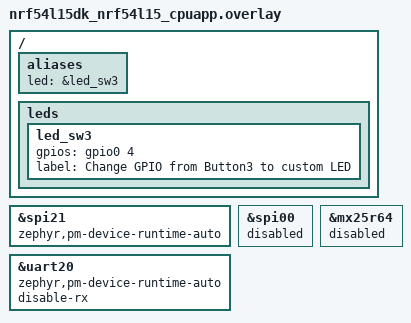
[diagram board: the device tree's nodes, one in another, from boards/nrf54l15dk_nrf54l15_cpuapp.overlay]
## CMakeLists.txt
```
#
# Copyright (c) 2024 Nordic Semiconductor
#
# SPDX-License-Identifier: LicenseRef-Nordic-5-Clause
#

cmake_minimum_required(VERSION 3.13.1)
find_package(Zephyr REQUIRED HINTS $ENV{ZEPHYR_BASE})
zephyr_include_directories(include)

project(spi)

target_sources(app PRIVATE ./../common/main.c)
target_sources(app PRIVATE src/driver_test.c)
```

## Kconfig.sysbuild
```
#
# Copyright (c) 2024 Nordic Semiconductor ASA
#
# SPDX-License-Identifier: LicenseRef-Nordic-5-Clause
#

config REMOTE_BOARD
	string "The board used for remote target"

source "share/sysbuild/Kconfig"
```

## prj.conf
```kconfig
# Drivers and peripherals
CONFIG_SPI=y
CONFIG_ASSERT=y

# Enable runtime power management for peripheral
CONFIG_PM_DEVICE=y
CONFIG_PM_DEVICE_RUNTIME=y

CONFIG_PM=y
CONFIG_POWEROFF=y

# Enable for debugging purposes only
CONFIG_CONSOLE=n
CONFIG_UART_CONSOLE=n
CONFIG_SERIAL=n
CONFIG_BOOT_BANNER=n
CONFIG_NCS_BOOT_BANNER=n
```

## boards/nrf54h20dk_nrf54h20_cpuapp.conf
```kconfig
#
# Copyright (c) 2025 Nordic Semiconductor ASA
#
# SPDX-License-Identifier: LicenseRef-Nordic-5-Clause
#
CONFIG_PM_S2RAM=y

CONFIG_SOC_NRF54H20_CPURAD_ENABLE=y
```

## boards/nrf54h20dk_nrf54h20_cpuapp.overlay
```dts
/ {
	aliases {
		led = &led0;
		/delete-property/ led1;
	};
};

/delete-node/ &led1;

dut_spi: &spi131 {
	zephyr,pm-device-runtime-auto;
};

&exmif {
	status = "disabled";
};

&uart136 {
	zephyr,pm-device-runtime-auto;
	disable-rx;
};
```

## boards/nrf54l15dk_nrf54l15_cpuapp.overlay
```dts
/* Can not use led_0 nor led_3 because pca63565
 * uses those GPIOs for other purposes.
 *
 * PPK takes cpuapp active/sleep state from P0.04
 * which is Button3 in the board definition.
 * Moreover, Buttons have (GPIO_PULL_UP | GPIO_ACTIVE_LOW).
 */

/ {
	aliases {
		led = &led_sw3;
		/delete-property/ sw3;
	};
};

/delete-node/ &button3;

/ {
	leds {
		led_sw3: led_sw3 {
			gpios = <&gpio0 4 GPIO_ACTIVE_HIGH>;
			label = "Change GPIO from Button3 to custom LED";
		};
	};
};

dut_spi: &spi21 {
	zephyr,pm-device-runtime-auto;
};

/* Disable mx25r64. */
&spi00 {
	status = "disabled";
};

&mx25r64 {
	status = "disabled";
};

&uart20 {
	zephyr,pm-device-runtime-auto;
	disable-rx;
};
```

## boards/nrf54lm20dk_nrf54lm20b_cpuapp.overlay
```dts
/*
 * Copyright (c) 2026 Nordic Semiconductor ASA
 *
 * SPDX-License-Identifier: LicenseRef-Nordic-5-Clause
 */

/ {
	aliases {
		led = &led_custom0;
	};
};

/ {
	leds {
		led_custom0: led_custom0 {
			gpios = <&gpio3 0 GPIO_ACTIVE_HIGH>;
			label = "Custom LED due to collision with PCA63565";
		};
	};
};

&spi21 {
	zephyr,pm-device-runtime-auto;
};

/* Disable mx25r64. */
&spi00 {
	status = "disabled";
};
```

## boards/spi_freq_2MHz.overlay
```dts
&dut_spi {
	max-frequency = <DT_FREQ_M(2)>;
};
```

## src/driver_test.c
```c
/*
 * Copyright (c) 2024 Nordic Semiconductor ASA
 *
 * SPDX-License-Identifier: LicenseRef-Nordic-5-Clause
 */

#include <zephyr/drivers/spi.h>
#include <zephyr/kernel.h>

#define READ_COMMAND (0x0B)
#define DEVID_AD_ADDRESS (0x0)
#define DEVID_AD_VAL (0xAD)
#define DEVID_MST_VAL (0x1D)
#define PARTID_VAL (0xF2)

#define SPIOP	SPI_WORD_SET(8) | SPI_TRANSFER_MSB

static bool suspend_req;

bool self_suspend_req(void)
{
	suspend_req = true;
	return true;
}

void thread_definition(void)
{
	int ret;
	struct spi_dt_spec spispec = SPI_DT_SPEC_GET(DT_ALIAS(accel0), SPIOP);

	uint8_t tx_buffer[5] = {READ_COMMAND, DEVID_AD_ADDRESS, 0xFF, 0xFF, 0xFF};
	uint8_t rx_buffer[5] = {0, 0, 0, 0, 0};
	struct spi_buf tx_spi_buf		= {.buf = tx_buffer, .len = 5};
	struct spi_buf_set tx_spi_buf_set	= {.buffers = &tx_spi_buf, .count = 1};
	struct spi_buf rx_spi_bufs		= {.buf = rx_buffer, .len = 5};
	struct spi_buf_set rx_spi_buf_set	= {.buffers = &rx_spi_bufs, .count = 1};

	while (1) {
		if (suspend_req) {
			suspend_req = false;
			k_thread_suspend(k_current_get());
		}

		ret = spi_transceive_dt(&spispec, &tx_spi_buf_set, &rx_spi_buf_set);
		__ASSERT(ret == 0, "spi_transceive_dt() returned %d", ret);

		/* Check if communication with adxl362 was successful. */
		__ASSERT(rx_buffer[2] == DEVID_AD_VAL,
			"Invalid DEVID_AD, got %u, expected %u\n", rx_buffer[2], DEVID_AD_VAL);
		__ASSERT(rx_buffer[3] == DEVID_MST_VAL,
			"Invalid DEVID_MST, got %u, expected %u\n", rx_buffer[3], DEVID_MST_VAL);
		__ASSERT(rx_buffer[4] == PARTID_VAL,
			"Invalid PARTID, got %u, expected %u\n", rx_buffer[4], PARTID_VAL);
		rx_buffer[2] = 0;
		rx_buffer[3] = 0;
		rx_buffer[4] = 0;
	};
};
```
